# nrf9220_cellrf register map
Vendor: Nordic Semiconductor; Series: nRF92; File version: 1
CPU: CM0 r0p0, little endian, no MPU, no FPU, 2 interrupt priority bits, 33 interrupts
Registers are 32-bit, read-write, reset 0x0 unless marked. A register's access mark holds for its fields unless they carry their own. Offsets are from the block's base; [hi:lo] are bit positions; 'fields as' and 'values as' point back to an identical list.

## RFCORESERVICES — AhmaRfSubsystem general control register map AhmaRfSubsystem general control register map
Base 0x46009000
0x00 TASKS_RUNWARMBOOT wo — Other CPUs can use this task to wake Cortex-M0 up when it has gone to sleep
  [0] TASKS_RUNWARMBOOT
    1=Trigger task
0x04 TASKS_RUNDEBUGBOOT wo — Debugger can use this task to wake Cortex-M0 up when it has gone to sleep
  [0] TASKS_RUNDEBUGBOOT
    1=Trigger task
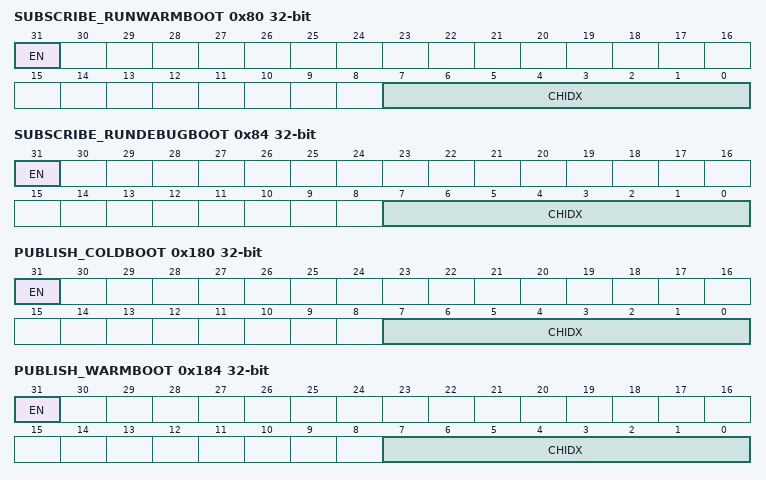
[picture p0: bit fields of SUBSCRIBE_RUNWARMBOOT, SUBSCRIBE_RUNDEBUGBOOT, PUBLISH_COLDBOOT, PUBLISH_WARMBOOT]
0x80 SUBSCRIBE_RUNWARMBOOT — Subscribe configuration for task RUNWARMBOOT
  [31] EN
    0=Disabled (Disable subscription); 1=Enabled (Enable subscription)
  [7:0] CHIDX — DPPI channel that task RUNWARMBOOT will subscribe to
0x84 SUBSCRIBE_RUNDEBUGBOOT — Subscribe configuration for task RUNDEBUGBOOT
  [31] EN
    values as SUBSCRIBE_RUNWARMBOOT.EN
  [7:0] CHIDX — DPPI channel that task RUNDEBUGBOOT will subscribe to
0x100 EVENTS_COLDBOOT — This IRQ is triggered to boot the Cortex-M0 up. This IRQ is enabled by default but due to tool flow limitation that is not visible in INTEN reset value.
  [0] EVENTS_COLDBOOT
    0=NotGenerated (Event not generated); 1=Generated (Event generated)
0x104 EVENTS_WARMBOOT — This IRQ is triggered by the WARMBOOT task to wake the Cortex-M0 up if needed. This IRQ is enabled by default but due to tool flow limitation that is not visible in INTEN reset value.
  [0] EVENTS_WARMBOOT
    values as EVENTS_COLDBOOT.EVENTS_COLDBOOT
0x108 EVENTS_DEBUGBOOT — This IRQ is triggered by the DEBUGBOOT task to wake the Cortex-M0 up if needed. This IRQ is enabled by default but due to tool flow limitation that is not visible in INTEN reset value
  [0] EVENTS_DEBUGBOOT
    values as EVENTS_COLDBOOT.EVENTS_COLDBOOT
0x10C EVENTS_ACKLOAD1V8PE — Rising edge on ack detected for the REQLOAD1V8 request
  [0] EVENTS_ACKLOAD1V8PE
    values as EVENTS_COLDBOOT.EVENTS_COLDBOOT
0x110 EVENTS_ACKLOAD1V8NE — Falling edge on ack detected for the REQLOAD1V8 request
  [0] EVENTS_ACKLOAD1V8NE
    values as EVENTS_COLDBOOT.EVENTS_COLDBOOT
0x114 EVENTS_ACKCLEAN1V8PE — Rising edge on ack detected for the REQCLEAN1V8 request
  [0] EVENTS_ACKCLEAN1V8PE
    values as EVENTS_COLDBOOT.EVENTS_COLDBOOT
0x118 EVENTS_ACKCLEAN1V8NE — Falling edge on ack detected for the REQCLEAN1V8 request
  [0] EVENTS_ACKCLEAN1V8NE
    values as EVENTS_COLDBOOT.EVENTS_COLDBOOT
0x11C EVENTS_ACKUPSCALE0V8PE — Rising edge on ack detected for the REQUPSCALE0V8 request
  [0] EVENTS_ACKUPSCALE0V8PE
    values as EVENTS_COLDBOOT.EVENTS_COLDBOOT
0x120 EVENTS_ACKUPSCALE0V8NE — Falling edge on ack detected for the REQUPSCALE0V8 request
  [0] EVENTS_ACKUPSCALE0V8NE
    values as EVENTS_COLDBOOT.EVENTS_COLDBOOT
0x124 EVENTS_ACKCLEAN0V8PE — Rising edge on ack detected for the REQCLEAN0V8 request
  [0] EVENTS_ACKCLEAN0V8PE
    values as EVENTS_COLDBOOT.EVENTS_COLDBOOT
0x128 EVENTS_ACKCLEAN0V8NE — Falling edge on ack detected for the REQCLEAN0V8 request
  [0] EVENTS_ACKCLEAN0V8NE
    values as EVENTS_COLDBOOT.EVENTS_COLDBOOT
0x180 PUBLISH_COLDBOOT — Publish configuration for event COLDBOOT
  [31] EN
    0=Disabled (Disable publishing); 1=Enabled (Enable publishing)
  [7:0] CHIDX — DPPI channel that event COLDBOOT will publish to
0x184 PUBLISH_WARMBOOT — Publish configuration for event WARMBOOT
  [31] EN
    values as PUBLISH_COLDBOOT.EN
  [7:0] CHIDX — DPPI channel that event WARMBOOT will publish to
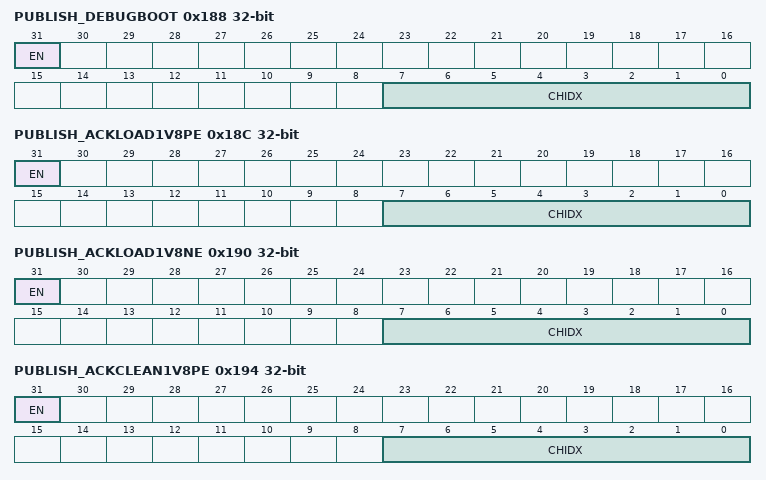
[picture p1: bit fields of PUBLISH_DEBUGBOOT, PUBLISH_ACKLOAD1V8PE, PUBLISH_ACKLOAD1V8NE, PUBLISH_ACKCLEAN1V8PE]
0x188 PUBLISH_DEBUGBOOT — Publish configuration for event DEBUGBOOT
  [31] EN
    values as PUBLISH_COLDBOOT.EN
  [7:0] CHIDX — DPPI channel that event DEBUGBOOT will publish to
0x18C PUBLISH_ACKLOAD1V8PE — Publish configuration for event ACKLOAD1V8PE
  [31] EN
    values as PUBLISH_COLDBOOT.EN
  [7:0] CHIDX — DPPI channel that event ACKLOAD1V8PE will publish to
0x190 PUBLISH_ACKLOAD1V8NE — Publish configuration for event ACKLOAD1V8NE
  [31] EN
    values as PUBLISH_COLDBOOT.EN
  [7:0] CHIDX — DPPI channel that event ACKLOAD1V8NE will publish to
0x194 PUBLISH_ACKCLEAN1V8PE — Publish configuration for event ACKCLEAN1V8PE
  [31] EN
    values as PUBLISH_COLDBOOT.EN
  [7:0] CHIDX — DPPI channel that event ACKCLEAN1V8PE will publish to
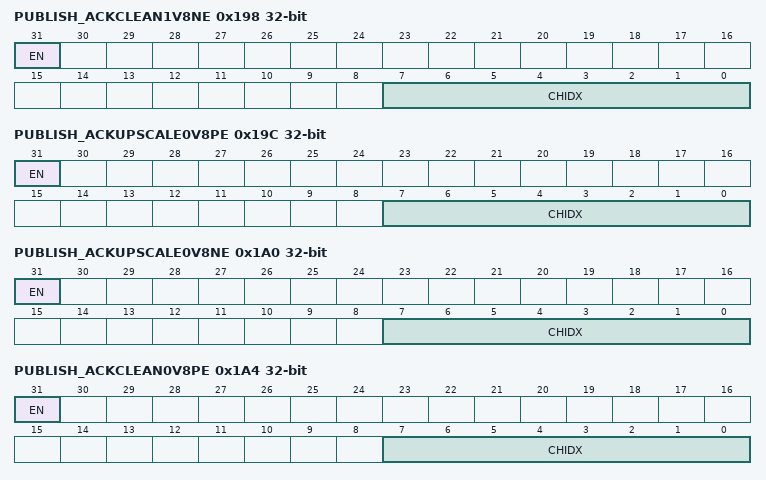
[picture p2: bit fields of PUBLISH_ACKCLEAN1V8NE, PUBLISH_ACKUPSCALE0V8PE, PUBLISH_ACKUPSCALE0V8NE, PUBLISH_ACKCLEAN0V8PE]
0x198 PUBLISH_ACKCLEAN1V8NE — Publish configuration for event ACKCLEAN1V8NE
  [31] EN
    values as PUBLISH_COLDBOOT.EN
  [7:0] CHIDX — DPPI channel that event ACKCLEAN1V8NE will publish to
0x19C PUBLISH_ACKUPSCALE0V8PE — Publish configuration for event ACKUPSCALE0V8PE
  [31] EN
    values as PUBLISH_COLDBOOT.EN
  [7:0] CHIDX — DPPI channel that event ACKUPSCALE0V8PE will publish to
0x1A0 PUBLISH_ACKUPSCALE0V8NE — Publish configuration for event ACKUPSCALE0V8NE
  [31] EN
    values as PUBLISH_COLDBOOT.EN
  [7:0] CHIDX — DPPI channel that event ACKUPSCALE0V8NE will publish to
0x1A4 PUBLISH_ACKCLEAN0V8PE — Publish configuration for event ACKCLEAN0V8PE
  [31] EN
    values as PUBLISH_COLDBOOT.EN
  [7:0] CHIDX — DPPI channel that event ACKCLEAN0V8PE will publish to
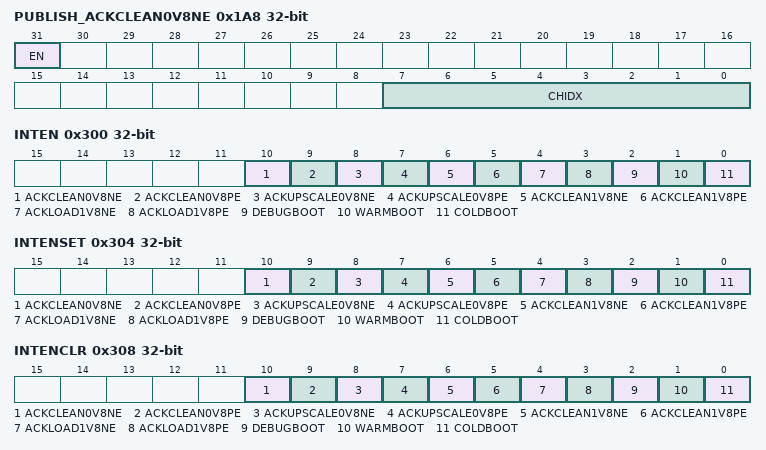
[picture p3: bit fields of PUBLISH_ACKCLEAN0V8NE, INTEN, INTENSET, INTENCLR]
0x1A8 PUBLISH_ACKCLEAN0V8NE — Publish configuration for event ACKCLEAN0V8NE
  [31] EN
    values as PUBLISH_COLDBOOT.EN
  [7:0] CHIDX — DPPI channel that event ACKCLEAN0V8NE will publish to
0x300 INTEN — Enable or disable interrupt
  [all] fields
    0=Disabled; 1=Enabled
  [10] ACKCLEAN0V8NE — Enable or disable interrupt for event ACKCLEAN0V8NE
  [9] ACKCLEAN0V8PE — Enable or disable interrupt for event ACKCLEAN0V8PE
  [8] ACKUPSCALE0V8NE — Enable or disable interrupt for event ACKUPSCALE0V8NE
  [7] ACKUPSCALE0V8PE — Enable or disable interrupt for event ACKUPSCALE0V8PE
  [6] ACKCLEAN1V8NE — Enable or disable interrupt for event ACKCLEAN1V8NE
  [5] ACKCLEAN1V8PE — Enable or disable interrupt for event ACKCLEAN1V8PE
  [4] ACKLOAD1V8NE — Enable or disable interrupt for event ACKLOAD1V8NE
  [3] ACKLOAD1V8PE — Enable or disable interrupt for event ACKLOAD1V8PE
  [2] DEBUGBOOT — Enable or disable interrupt for event DEBUGBOOT
  [1] WARMBOOT — Enable or disable interrupt for event WARMBOOT
  [0] COLDBOOT — Enable or disable interrupt for event COLDBOOT
0x304 INTENSET — Enable interrupt
  [all] fields
    on read: 0=Disabled (Read: Disabled); 1=Enabled (Read: Enabled) | on write: 1=Set (Enable)
  [10] ACKCLEAN0V8NE — Write '1' to enable interrupt for event ACKCLEAN0V8NE
  [9] ACKCLEAN0V8PE — Write '1' to enable interrupt for event ACKCLEAN0V8PE
  [8] ACKUPSCALE0V8NE — Write '1' to enable interrupt for event ACKUPSCALE0V8NE
  [7] ACKUPSCALE0V8PE — Write '1' to enable interrupt for event ACKUPSCALE0V8PE
  [6] ACKCLEAN1V8NE — Write '1' to enable interrupt for event ACKCLEAN1V8NE
  [5] ACKCLEAN1V8PE — Write '1' to enable interrupt for event ACKCLEAN1V8PE
  [4] ACKLOAD1V8NE — Write '1' to enable interrupt for event ACKLOAD1V8NE
  [3] ACKLOAD1V8PE — Write '1' to enable interrupt for event ACKLOAD1V8PE
  [2] DEBUGBOOT — Write '1' to enable interrupt for event DEBUGBOOT
  [1] WARMBOOT — Write '1' to enable interrupt for event WARMBOOT
  [0] COLDBOOT — Write '1' to enable interrupt for event COLDBOOT
0x308 INTENCLR — Disable interrupt
  [all] fields
    on read: 0=Disabled (Read: Disabled); 1=Enabled (Read: Enabled) | on write: 1=Clear (Disable)
  [10] ACKCLEAN0V8NE — Write '1' to disable interrupt for event ACKCLEAN0V8NE
  [9] ACKCLEAN0V8PE — Write '1' to disable interrupt for event ACKCLEAN0V8PE
  [8] ACKUPSCALE0V8NE — Write '1' to disable interrupt for event ACKUPSCALE0V8NE
  [7] ACKUPSCALE0V8PE — Write '1' to disable interrupt for event ACKUPSCALE0V8PE
  [6] ACKCLEAN1V8NE — Write '1' to disable interrupt for event ACKCLEAN1V8NE
  [5] ACKCLEAN1V8PE — Write '1' to disable interrupt for event ACKCLEAN1V8PE
  [4] ACKLOAD1V8NE — Write '1' to disable interrupt for event ACKLOAD1V8NE
  [3] ACKLOAD1V8PE — Write '1' to disable interrupt for event ACKLOAD1V8PE
  [2] DEBUGBOOT — Write '1' to disable interrupt for event DEBUGBOOT
  [1] WARMBOOT — Write '1' to disable interrupt for event WARMBOOT
  [0] COLDBOOT — Write '1' to disable interrupt for event COLDBOOT
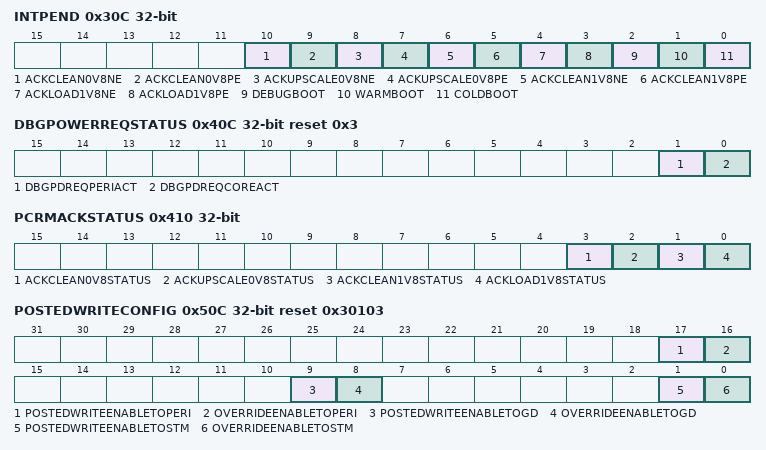
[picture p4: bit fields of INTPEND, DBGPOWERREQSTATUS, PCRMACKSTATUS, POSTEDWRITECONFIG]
0x30C INTPEND ro — Pending interrupts
  [all] fields
    on read: 0=NotPending (Read: Not pending); 1=Pending (Read: Pending)
  [10] ACKCLEAN0V8NE — Read pending status of interrupt for event ACKCLEAN0V8NE
  [9] ACKCLEAN0V8PE — Read pending status of interrupt for event ACKCLEAN0V8PE
  [8] ACKUPSCALE0V8NE — Read pending status of interrupt for event ACKUPSCALE0V8NE
  [7] ACKUPSCALE0V8PE — Read pending status of interrupt for event ACKUPSCALE0V8PE
  [6] ACKCLEAN1V8NE — Read pending status of interrupt for event ACKCLEAN1V8NE
  [5] ACKCLEAN1V8PE — Read pending status of interrupt for event ACKCLEAN1V8PE
  [4] ACKLOAD1V8NE — Read pending status of interrupt for event ACKLOAD1V8NE
  [3] ACKLOAD1V8PE — Read pending status of interrupt for event ACKLOAD1V8PE
  [2] DEBUGBOOT — Read pending status of interrupt for event DEBUGBOOT
  [1] WARMBOOT — Read pending status of interrupt for event WARMBOOT
  [0] COLDBOOT — Read pending status of interrupt for event COLDBOOT
0x400 CKREQSTATUS ro — Clock request status
  [10:0] CKREQSTATUS — Clock request status for each peripheral in AhmaRf Core
0x404 CPUID ro reset 0x6 — AhmaRf Cortex-M0 CPU ID
  [31:0] CPUID — AhmaRf Cortex-M0 system-wide CPU ID
0x408 ISOLATEPERISTATUS ro — PERI_ACT power domain isolation status
  [0] ISOLATEPERITOP
0x40C DBGPOWERREQSTATUS ro reset 0x3 — Debug power request status
  [1] DBGPDREQPERIACT — Status of signal dbgPdReqAhmaRf_PeriAct. It is a debug power request for PD_CORE from Trace and Debug system
  [0] DBGPDREQCOREACT — Status of signal dbgPdReqAhmaRf_CoreAct. It is a debug power request for PD_CORE from Trace and Debug system
0x410 PCRMACKSTATUS ro — PCRM acknowledgement status
  [all] fields
    0=AckNotActive; 1=AckActive
  [3] ACKCLEAN0V8STATUS — Power request acknowledgement status for 0V8 clean supply
  [2] ACKUPSCALE0V8STATUS — Power request acknowledgement status for 0V8 upscale supply
  [1] ACKCLEAN1V8STATUS — Power request acknowledgement status for 1V8 clean supply
  [0] ACKLOAD1V8STATUS — Power request acknowledgement status for 1V8 load supply
0x504 DELAYREGCONFIG — Delay Register Configuration Register
  [4:0] DELAYREGCONFIG — Number of wait states to introduce on transfers to/from the DELAYREG register
0x508 POWERCLOCKMODE — Power and clock mode
  [1:0] POWERCLOCKMODE — Core domain power and clock mode
    0=Power_Off (Core domain is allowed to power off); 1=Clocks_Off (Core domain is not allowed to power off, but is allowed to turn its clocks off); 2=Clocks_Gated (Core domain is not allowed to power off, and its clock generators are kept running while the clocks themselves may be gated); 3=All_On (Core domain is forced to have its clocks running)
0x50C POSTEDWRITECONFIG reset 0x30103 — Posted write configuration for CM0
  [17] POSTEDWRITEENABLETOPERI — Override value for writes to AhmaRfPeri (only used when OVERRIDEENABLETOPERI is Forced)
    0=ForceNonPosted (Writes to AhmaRfPeri are performed using non-posted writes); 1=ForcePosted (Writes to AhmaRfPeri are performed using posted writes)
  [16] OVERRIDEENABLETOPERI — Override enable for writes to AhmaRfPeri
    0=NotForced (Writes to AhmaRfPeri are performed as specified by CM0); 1=Forced (Writes to AhmaRfPeri are forced to be either posted or non-posted based on POSTEDWRITEENABLETOGD)
  [9] POSTEDWRITEENABLETOGD — Override value for writes to the GD_UP bus (other than STM; only used when OVERRIDEENABLETOGD is Forced)
    0=ForceNonPosted (Writes to GD_UP are performed using non-posted writes); 1=ForcePosted (Writes to GD_UP are performed using posted writes)
  [8] OVERRIDEENABLETOGD — Override enable for writes to the GD_UP bus (other than STM)
    0=NotForced (Writes to GD_UP are performed as specified by CM0); 1=Forced (Writes to GD_UP are forced to be either posted or non-posted based on POSTEDWRITEENABLETOGD)
  [1] POSTEDWRITEENABLETOSTM — Override value for writes to STM (only used when OVERRIDEENABLETOSTM is Forced)
    0=ForceNonPosted (Writes to STM are performed using non-posted writes); 1=ForcePosted (Writes to STM are performed using posted writes)
  [0] OVERRIDEENABLETOSTM — Override enable for writes to STM
    0=NotForced (Writes to STM are performed as specified by CM0); 1=Forced (Writes to STM are forced to be either posted or non-posted based on POSTEDWRITEENABLETOSTM)
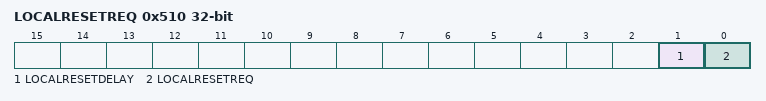
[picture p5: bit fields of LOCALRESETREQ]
0x510 LOCALRESETREQ — Local reset request for Cellular RF
  [1] LOCALRESETDELAY — Local reset request delay after register write.
    0=16ClockCycles (Local reset request is generated 16 clock cycles after the LOCALRESETREQ bit is written.); 1=32ClockCycles (Local reset request is generated 32 clock cycles after the LOCALRESETREQ bit is written.)
  [0] LOCALRESETREQ — Cellular RF local reset request. This register will automatically be cleared when the local reset occurs.
0x514 REQLOAD1V8 — Request load current estimate increase for VDD_AO_1V8 rail. The current estimate value is stored in PCRM CONFIG.LOAD register
  [0] REQLOAD1V8 — Request load current for VDD_AO_1V8 rail.
    0=NotRequested (Load current not requested.); 1=Requested (Load current requested.)
0x518 REQCLEAN1V8 — Request clean power for VDD_AO_1V8 rail
  [0] REQCLEAN1V8 — Request clean power for VDD_AO_1V8 rail.
    0=NotRequested (Clean power not requested.); 1=Requested (Clean power requested.)
0x51C REQUPSCALE0V8 — Request voltage level upscaling for VDD_AO_0V8 rail
  [0] REQUPSCALE0V8 — Request voltage level upscaling for VDD_AO_0V8 rail.
    0=NotRequested (Voltage upscaling not requested.); 1=Requested (Voltage upscaling requested.)
0x520 REQCLEAN0V8 — Request clean power for VDD_AO_0V8 rail
  [0] REQCLEAN0V8 — Request clean power for VDD_AO_0V8 rail.
    values as REQCLEAN1V8.REQCLEAN1V8
0x600 DELAYREG — Delay Register
  [31:0] DELAYREG — General-purpose register that produces a number of wait states on the bus (see DELAYREGCONFIG)
